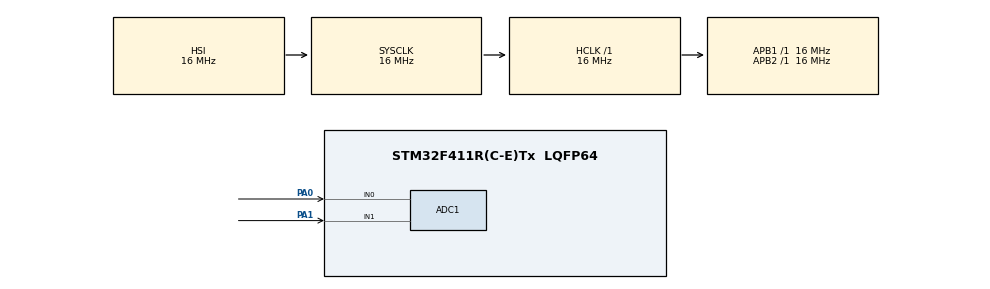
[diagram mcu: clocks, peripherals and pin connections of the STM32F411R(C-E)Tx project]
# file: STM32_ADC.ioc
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ADC1.Channel-1\#ChannelRegularConversion=ADC_CHANNEL_1
ADC1.NbrOfConversionFlag=1
ADC1.Rank-1\#ChannelRegularConversion=1
ADC1.SamplingTime-1\#ChannelRegularConversion=ADC_SAMPLETIME_3CYCLES
ADC1.master=1
Mcu.Family=STM32F4
Mcu.Name=STM32F411R(C-E)Tx
Mcu.Package=LQFP64
NVIC.PriorityGroup=NVIC_PRIORITYGROUP_4
PA0-WKUP.Signal=ADCx_IN0
PA1.Signal=ADCx_IN1
ProjectManager.HeapSize=0x200
ProjectManager.StackSize=0x400
ProjectManager.TargetToolchain=STM32CubeIDE
RCC.AHBFreq_Value=16000000
RCC.APB1Freq_Value=16000000
RCC.APB2Freq_Value=16000000
RCC.CortexFreq_Value=16000000
RCC.HSE_VALUE=25000000
RCC.HSI_VALUE=16000000
RCC.LSE_VALUE=32768
RCC.SYSCLKFreq_VALUE=16000000
RCC.VCOOutputFreq_Value=192000000
SH.ADCx_IN0.0=ADC1_IN0,IN0
SH.ADCx_IN1.0=ADC1_IN1,IN1
board=custom

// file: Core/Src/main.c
/* USER CODE BEGIN Header */
/**
  ******************************************************************************
  * @file           : main.c
  * @brief          : Main program body
  ******************************************************************************
  * @attention
  *
  * Copyright (c) 2026 STMicroelectronics.
  * All rights reserved.
  *
  * This software is licensed under terms that can be found in the LICENSE file
  * in the root directory of this software component.
  * If no LICENSE file comes with this software, it is provided AS-IS.
  *
  ******************************************************************************
  */
/* USER CODE END Header */
#include "main.h"
#include "adc.h"
#include "gpio.h"

/* USER CODE BEGIN PV */
uint32_t adc_value_0 = 0; // Variable to store the ADC value channel 0
float voltage_0 = 0.0; // Variable to store the converted voltage channel 0
uint32_t adc_value_1 = 0; // Variable to store the ADC value channel 1
float voltage_1 = 0.0; // Variable to store the converted voltage channel 1

/* USER CODE END PV */

void SystemClock_Config(void);

int main(void)
{

  /* MCU Configuration--------------------------------------------------------*/

  /* Reset of all peripherals, Initializes the Flash interface and the Systick. */
  HAL_Init();

  /* Configure the system clock */
  SystemClock_Config();

  /* Initialize all configured peripherals */
  MX_GPIO_Init();
  MX_ADC1_Init();

  /* Infinite loop */
  /* USER CODE BEGIN WHILE */
  while (1)
  {
    adc_value_0 = Read_ADC_Channel(ADC_CHANNEL_0); // Read ADC channel 0
    adc_value_1 = Read_ADC_Channel(ADC_CHANNEL_1); // Read ADC channel 1
    voltage_0 = ADC_to_Voltage(adc_value_0); // Convert ADC value to voltage for channel 0
    voltage_1 = ADC_to_Voltage(adc_value_1); // Convert ADC
    //****the code can be written also like this
    //voltage_0 = ADC_to_Voltage(Read_ADC_Channel(ADC_CHANNEL_0)); // Convert ADC value to voltage for channel 0
    //voltage_1 = ADC_to_Voltage(Read_ADC_Channel(ADC_CHANNEL_1)); // Convert ADC value to voltage for channel 1

    HAL_Delay(50);  // Read every 50 ms
    /* USER CODE END WHILE */

    /* USER CODE BEGIN 3 */
  }
}

void SystemClock_Config(void)
{
  RCC_OscInitTypeDef RCC_OscInitStruct = {0};
  RCC_ClkInitTypeDef RCC_ClkInitStruct = {0};

  /** Configure the main internal regulator output voltage
  */
  __HAL_RCC_PWR_CLK_ENABLE();
  __HAL_PWR_VOLTAGESCALING_CONFIG(PWR_REGULATOR_VOLTAGE_SCALE1);

  /** Initializes the RCC Oscillators according to the specified parameters
  * in the RCC_OscInitTypeDef structure.
  */
  RCC_OscInitStruct.OscillatorType = RCC_OSCILLATORTYPE_HSI;
  RCC_OscInitStruct.HSIState = RCC_HSI_ON;
  RCC_OscInitStruct.HSICalibrationValue = RCC_HSICALIBRATION_DEFAULT;
  RCC_OscInitStruct.PLL.PLLState = RCC_PLL_NONE;
  if (HAL_RCC_OscConfig(&RCC_OscInitStruct) != HAL_OK)
  {
    Error_Handler();
  }

  /** Initializes the CPU, AHB and APB buses clocks
  */
  RCC_ClkInitStruct.ClockType = RCC_CLOCKTYPE_HCLK|RCC_CLOCKTYPE_SYSCLK
                              |RCC_CLOCKTYPE_PCLK1|RCC_CLOCKTYPE_PCLK2;
  RCC_ClkInitStruct.SYSCLKSource = RCC_SYSCLKSOURCE_HSI;
  RCC_ClkInitStruct.AHBCLKDivider = RCC_SYSCLK_DIV1;
  RCC_ClkInitStruct.APB1CLKDivider = RCC_HCLK_DIV1;
  RCC_ClkInitStruct.APB2CLKDivider = RCC_HCLK_DIV1;

  if (HAL_RCC_ClockConfig(&RCC_ClkInitStruct, FLASH_LATENCY_0) != HAL_OK)
  {
    Error_Handler();
  }
}

void Error_Handler(void)
{
  __disable_irq();
  while (1)
  {
  }
}
